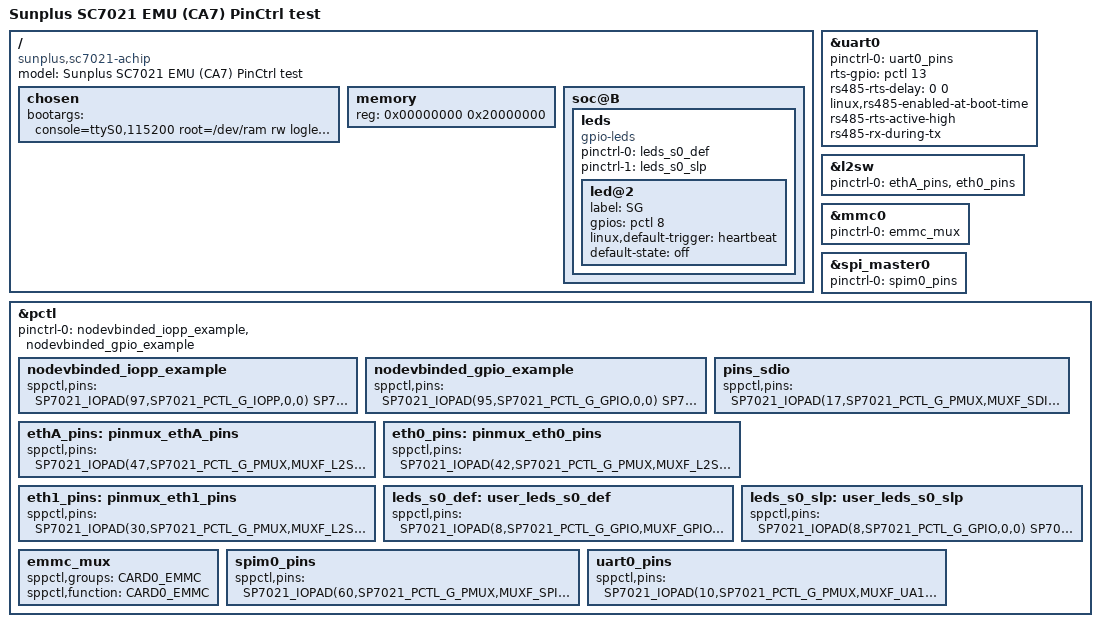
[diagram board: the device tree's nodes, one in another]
/dts-v1/;

#include "pentagram-sp7021-achip.dtsi"

#include <dt-bindings/interrupt-controller/arm-gic.h>

/ {
	model = "Sunplus SC7021 EMU (CA7) PinCtrl test";
	compatible = "sunplus,sc7021-achip";

	chosen {
		bootargs = "console=ttyS0,115200 root=/dev/ram rw loglevel=8 earlyprintk";
	};

	memory {
		reg = <0x00000000 0x20000000>; /* 512MB */
	};
};

&uart0 {
 pinctrl-names = "default";
 pinctrl-0 = <&uart0_pins>;
 rts-gpio = <&pctl 13 GPIO_ACTIVE_HIGH>;
 rs485-rts-delay = <0 0>;
 linux,rs485-enabled-at-boot-time;
 rs485-rts-active-high;
 rs485-rx-during-tx;
};

&l2sw {
 pinctrl-names = "default";
 pinctrl-0 = <&ethA_pins &eth0_pins/* &eth1_pins*/>;
};

&mmc0 {
 pinctrl-names = "default";
 pinctrl-0 = <&emmc_mux>;
};

&spi_master0 {
 pinctrl-names = "default";
 pinctrl-0 = <&spim0_pins>;
};

&pctl {
 /*** all non-device binded that you want to set mode ***/
 pinctrl-names = "default";
 pinctrl-0 = <&nodevbinded_iopp_example &nodevbinded_gpio_example>;

 nodevbinded_iopp_example: nodevbinded_iopp_example {
    sppctl,pins = <
      SP7021_IOPAD(97,SP7021_PCTL_G_IOPP,0,0)
      SP7021_IOPAD(98,SP7021_PCTL_G_IOPP,0,0)
    >;
 };

 nodevbinded_gpio_example: nodevbinded_gpio_example {
    sppctl,pins = <
      SP7021_IOPAD(95,SP7021_PCTL_G_GPIO,0,0)
      SP7021_IOPAD(96,SP7021_PCTL_G_GPIO,0,0)
    >;
 };

 /* for all eth */
 pins_sdio: pins_sdio {
  sppctl,pins = <
       SP7021_IOPAD(17,SP7021_PCTL_G_PMUX,MUXF_SDIO_D1,0)
       SP7021_IOPAD(19,SP7021_PCTL_G_PMUX,MUXF_SDIO_D0,0)
       SP7021_IOPAD(21,SP7021_PCTL_G_PMUX,MUXF_SDIO_CLK,0)
       SP7021_IOPAD(23,SP7021_PCTL_G_PMUX,MUXF_SDIO_CMD,0)
       SP7021_IOPAD(25,SP7021_PCTL_G_PMUX,MUXF_SDIO_D3,0)
       SP7021_IOPAD(27,SP7021_PCTL_G_PMUX,MUXF_SDIO_D2,0)
  >;
 };
 /* for all eth */
 ethA_pins: pinmux_ethA_pins {
  sppctl,pins = <
       SP7021_IOPAD(47,SP7021_PCTL_G_PMUX,MUXF_L2SW_CLK_OUT,0)
       SP7021_IOPAD(41,SP7021_PCTL_G_PMUX,MUXF_L2SW_MAC_SMI_MDC,0)
       SP7021_IOPAD(40,SP7021_PCTL_G_PMUX,MUXF_L2SW_MAC_SMI_MDIO,0)
  >;
 };
 eth0_pins: pinmux_eth0_pins {
  sppctl,pins = <
       SP7021_IOPAD(42,SP7021_PCTL_G_PMUX,MUXF_L2SW_LED_FLASH0,0)
       SP7021_IOPAD(51,SP7021_PCTL_G_PMUX,MUXF_L2SW_LED_ON0,0)

       SP7021_IOPAD(50,SP7021_PCTL_G_PMUX,MUXF_L2SW_P0_MAC_RMII_TXEN,0)
       SP7021_IOPAD(48,SP7021_PCTL_G_PMUX,MUXF_L2SW_P0_MAC_RMII_TXD0,0)
       SP7021_IOPAD(49,SP7021_PCTL_G_PMUX,MUXF_L2SW_P0_MAC_RMII_TXD1,0)
       SP7021_IOPAD(44,SP7021_PCTL_G_PMUX,MUXF_L2SW_P0_MAC_RMII_CRSDV,0)
       SP7021_IOPAD(45,SP7021_PCTL_G_PMUX,MUXF_L2SW_P0_MAC_RMII_RXD0,0)
       SP7021_IOPAD(46,SP7021_PCTL_G_PMUX,MUXF_L2SW_P0_MAC_RMII_RXD1,0)
       SP7021_IOPAD(43,SP7021_PCTL_G_PMUX,MUXF_L2SW_P0_MAC_RMII_RXER,0)
  >;
 };
 eth1_pins: pinmux_eth1_pins {
  sppctl,pins = <
       SP7021_IOPAD(30,SP7021_PCTL_G_PMUX,MUXF_L2SW_LED_FLASH1,0)
       SP7021_IOPAD(39,SP7021_PCTL_G_PMUX,MUXF_L2SW_LED_ON1,0)

       SP7021_IOPAD(38,SP7021_PCTL_G_PMUX,MUXF_L2SW_P1_MAC_RMII_TXEN,0)
       SP7021_IOPAD(36,SP7021_PCTL_G_PMUX,MUXF_L2SW_P1_MAC_RMII_TXD0,0)
       SP7021_IOPAD(37,SP7021_PCTL_G_PMUX,MUXF_L2SW_P1_MAC_RMII_TXD1,0)
       SP7021_IOPAD(32,SP7021_PCTL_G_PMUX,MUXF_L2SW_P1_MAC_RMII_CRSDV,0)
       SP7021_IOPAD(33,SP7021_PCTL_G_PMUX,MUXF_L2SW_P1_MAC_RMII_RXD0,0)
       SP7021_IOPAD(34,SP7021_PCTL_G_PMUX,MUXF_L2SW_P1_MAC_RMII_RXD1,0)
       SP7021_IOPAD(31,SP7021_PCTL_G_PMUX,MUXF_L2SW_P1_MAC_RMII_RXER,0)
  >;
 };

 leds_s0_def: user_leds_s0_def {
    sppctl,pins = <
      SP7021_IOPAD(8,SP7021_PCTL_G_GPIO,MUXF_GPIO,SP7021_PCTL_L_INV)
      SP7021_IOPAD(9,SP7021_PCTL_G_GPIO,0,SP7021_PCTL_L_INV)
    >;
 };
 leds_s0_slp: user_leds_s0_slp {
    sppctl,pins = <
      SP7021_IOPAD(8,SP7021_PCTL_G_GPIO,0,0)
      SP7021_IOPAD(9,SP7021_PCTL_G_GPIO,0,0)
    >;
 };

 emmc_mux: emmc_mux {
    sppctl,groups = "CARD0_EMMC";
    sppctl,function = "CARD0_EMMC";
 };

 spim0_pins: spim0_pins {
  sppctl,pins = <
       SP7021_IOPAD(60,SP7021_PCTL_G_PMUX,MUXF_SPIM0_INT,0)
       SP7021_IOPAD(61,SP7021_PCTL_G_PMUX,MUXF_SPIM0_CLK,0)
       SP7021_IOPAD(61,SP7021_PCTL_G_PMUX,MUXF_SPIM0_EN,0)
       SP7021_IOPAD(63,SP7021_PCTL_G_PMUX,MUXF_SPIM0_DO,0)
       SP7021_IOPAD(64,SP7021_PCTL_G_PMUX,MUXF_SPIM0_DI,0)
  >;
 };

 uart0_pins: uart0_pins {
  sppctl,pins = <
       SP7021_IOPAD(10,SP7021_PCTL_G_PMUX,MUXF_UA1_TX,0)
       SP7021_IOPAD(11,SP7021_PCTL_G_PMUX,MUXF_UA1_RX,0)
       SP7021_IOPAD(12,SP7021_PCTL_G_PMUX,MUXF_UA1_CTS,0)
       SP7021_IOPAD(13,SP7021_PCTL_G_PMUX,MUXF_UA1_RTS,0)
  >;
 };

};

/* ----
 next one requires:

 CONFIG_NEW_LEDS=y
 CONFIG_LEDS_CLASS=y
 CONFIG_LEDS_GPIO=y
 CONFIG_LEDS_TRIGGERS=y
 CONFIG_LEDS_TRIGGER_HEARTBEAT=y
*/

/ {
	soc@B {
		leds {
		    pinctrl-names = "default", "sleep";
		    pinctrl-0 = <&leds_s0_def>;
		    pinctrl-1 = <&leds_s0_slp>;
		    compatible = "gpio-leds";
		    led@2 {
			label = "SG";
			gpios = <&pctl 8 GPIO_ACTIVE_HIGH>;
			linux,default-trigger = "heartbeat";
			default-state = "off";
		    };
		};
	};
};
